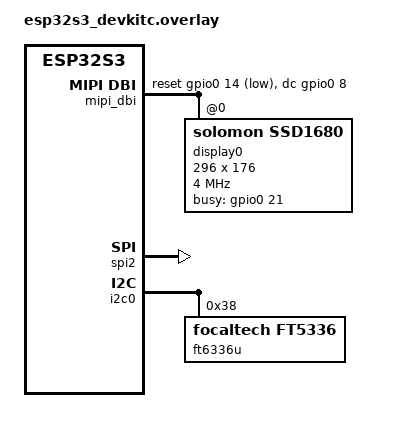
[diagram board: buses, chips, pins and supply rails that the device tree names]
/* Auto-generated by @typecad/framework-zephyr from typecad-hal.config.ts. */
/* Enables peripherals the program uses. West merges this over the board DT. */
#include <zephyr/dt-bindings/pinctrl/esp32s3-pinctrl.h>


&spim2_default {
    group1 {
        pinmux = <ESP32_PINMUX(13, ESP_FSPIQ_IN, ESP_NOSIG)>,
                 <ESP32_PINMUX(12, ESP_NOSIG, ESP_FSPICLK_OUT)>,
                 <ESP32_PINMUX(10, ESP_NOSIG, ESP_FSPICS0_OUT)>;
    };
    group2 {
        pinmux = <ESP32_PINMUX(11, ESP_NOSIG, ESP_FSPID_OUT)>;
        output-low;
    };
};

&dma {
    status = "okay";
};

&spi2 {
    status = "okay";
    cs-gpios = <&gpio0 5 GPIO_ACTIVE_LOW>;
    dma-enabled;
    dmas = <&dma 0>, <&dma 1>;
    dma-names = "rx", "tx";
};

/ {
    mipi_dbi: mipi-dbi {
        compatible = "zephyr,mipi-dbi-spi";
        spi-dev = <&spi2>;
        dc-gpios = <&gpio0 8 GPIO_ACTIVE_HIGH>;
        reset-gpios = <&gpio0 14 GPIO_ACTIVE_LOW>;
        write-only;
        #address-cells = <1>;
        #size-cells = <0>;
        display0: display@0 {
            compatible = "solomon,ssd1680";
            reg = <0>;
            mipi-max-frequency = <4000000>;
            mipi-mode = "MIPI_DBI_MODE_SPI_4WIRE";
            busy-gpios = <&gpio0 21 GPIO_ACTIVE_HIGH>;
            width = <296>;
            height = <176>;
        };
    };
};

&i2c0 {
    status = "okay";
    ft6336u: ft6336u@38 {
        compatible = "focaltech,ft5336";
        reg = <0x38>;
        swapped-x-y;
    };
};
